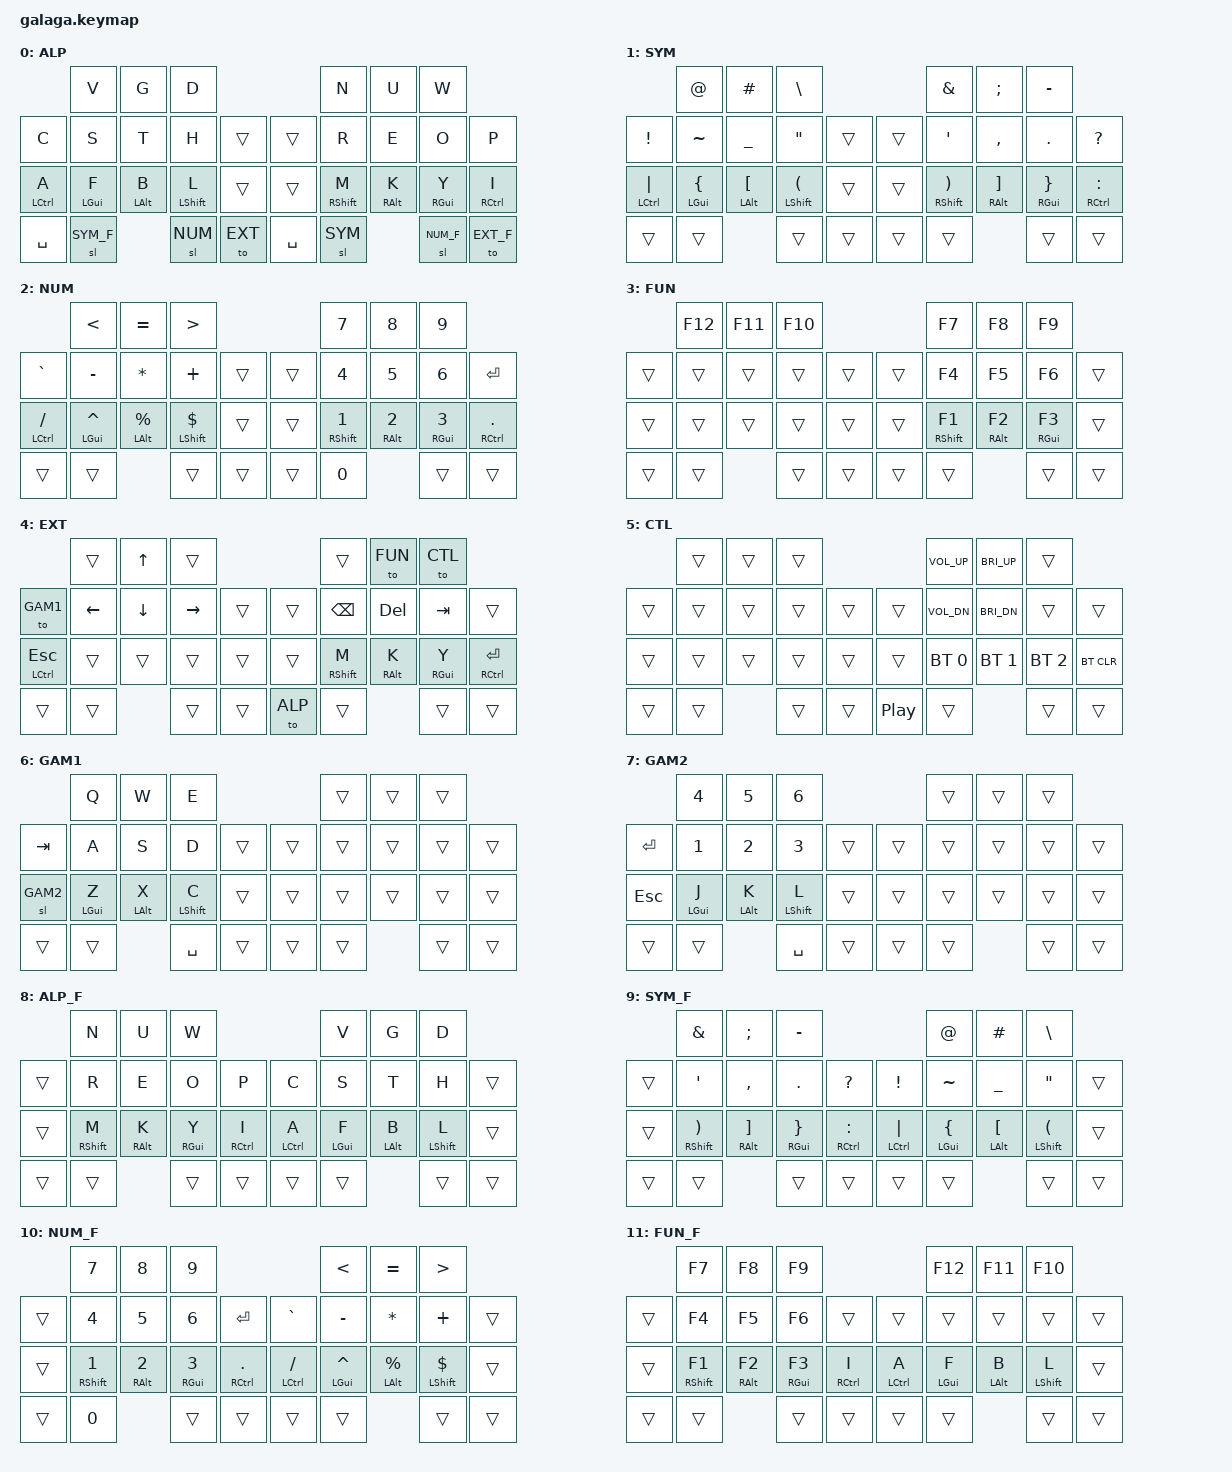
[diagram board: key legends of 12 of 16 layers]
#include <behaviors.dtsi>
#include <dt-bindings/zmk/keys.h>
#include <dt-bindings/zmk/bt.h>

/* Layers */
#define ALP 0
#define SYM 1
#define NUM 2
#define FUN 3
#define EXT 4
#define CTL 5
#define GAM1 6
#define GAM2 7
/* Flip hands */
#define ALP_F 8
#define SYM_F 9
#define NUM_F 10
#define FUN_F 11
#define EXT_F 12
#define CTL_F 13
#define GAM1_F 14
#define GAM2_F 15

/ {
  
  behaviors {
    hm: homerow_mods {
      compatible = "zmk,behavior-hold-tap";
      label = "HOMEROW_MODS";
      #binding-cells = <2>;
      tapping-term-ms = <300>;
      quick_tap_ms = <0>;
      flavor = "tap-preferred";
      bindings = <&kp>, <&kp>;
    };
  };

  /* TODO: figure out the correct key-positions for these combos */
  combos {
    compatible = "zmk,combos";
    combo_Z {
      layers = <0>;
      timeout-ms = <50>;
      key-positions = <17 18>;
      bindings = <&kp Z>;
    };
    combo_Q {
      layers = <0>;
      timeout-ms = <50>;
      key-positions = <18 19>;
      bindings = <&kp Q>;
    };
    combo_J {
      layers = <0>;
      timeout-ms = <50>;
      key-positions = <22 23>;
      bindings = <&kp J>;
    };
    combo_X {
      layers = <0>;
      timeout-ms = <50>;
      key-positions = <23 24>;
      bindings = <&kp X>;
    };
    combo_Z_F {
      layers = <8>;
      timeout-ms = <50>;
      key-positions = <22 23>;
      bindings = <&kp Z>;
    };
    combo_Q_F {
      layers = <8>;
      timeout-ms = <50>;
      key-positions = <23 24>;
      bindings = <&kp Q>;
    };
    combo_J_F {
      layers = <8>;
      timeout-ms = <50>;
      key-positions = <17 18>;
      bindings = <&kp J>;
    };
    combo_X_F {
      layers = <8>;
      timeout-ms = <50>;
      key-positions = <18 19>;
      bindings = <&kp X>;
    };
  };

  keymap {
    compatible = "zmk,keymap";

    ALP {
      bindings = <
                      &kp V       &kp G       &kp D                                      &kp N         &kp U       &kp W
        &kp C         &kp S       &kp T       &kp H         &trans            &trans     &kp R         &kp E       &kp O       &kp P
        &hm LCTRL A   &hm LGUI F  &hm LALT B  &hm LSHIFT L  &trans            &trans     &hm RSHIFT M  &hm RALT K  &hm RGUI Y  &hm RCTRL I
        &kp SPACE     &sl SYM_F               &sl NUM       &to EXT           &kp SPACE  &sl SYM                   &sl NUM_F   &to EXT_F
      >;
    };

    SYM {
      bindings = <
                        &kp AT         &kp HASH        &kp BSLH                                              &kp AMPS       &kp SEMI    &kp MINUS      
        &kp EXCL        &kp TILDE      &kp UNDER       &kp DQT            &trans            &trans           &kp SQT        &kp COMMA   &kp DOT    &kp QMARK
        &hm LCTRL PIPE  &hm LGUI LBRC  &hm LALT LBKT   &hm LSHIFT LPAR    &trans            &trans           &hm RSHIFT RPAR   &hm RALT RBKT  &hm RGUI RBRC &hm RCTRL COLON
        &trans          &trans                         &trans             &trans            &trans           &trans                     &trans     &trans
      >;
    };

    NUM {
      bindings = <
                        &kp LT         &kp EQUAL       &kp GT                                                &kp N7      &kp N8   &kp N9  
        &kp GRAVE       &kp MINUS      &kp STAR        &kp PLUS           &trans            &trans           &kp N4      &kp N5   &kp N6  &kp ENTER
        &hm LCTRL FSLH  &hm LGUI CARET &hm LALT PRCNT  &hm LSHIFT DLLR    &trans            &trans           &hm RSHIFT N1   &hm RALT N2  &hm RGUI N3 &hm RCTRL DOT
        &trans          &trans                         &trans             &trans            &trans           &kp N0                  &trans     &trans    
      >;
    };

    FUN {
      bindings = <
                        &kp F12        &kp F11         &kp F10                                               &kp F7         &kp F8      &kp F9      
        &trans          &trans         &trans          &trans             &trans            &trans           &kp F4         &kp F5      &kp F6     &trans    
        &trans          &trans         &trans          &trans             &trans            &trans           &hm RSHIFT F1  &hm RALT F2 &hm RGUI F3 &trans     
        &trans          &trans                         &trans             &trans            &trans           &trans                     &trans     &trans    
      >;
    };

    EXT {
      bindings = <
                        &trans         &kp UP          &trans                                                &trans         &to FUN     &to CTL    
        &to GAM1        &kp LEFT       &kp DOWN        &kp RIGHT          &trans            &trans           &kp BSPC       &kp DEL     &kp TAB    &trans    
        &hm LCTRL ESC   &trans         &trans          &trans             &trans            &trans           &hm RSHIFT M   &hm RALT K  &hm RGUI Y &hm RCTRL ENTER
        &trans          &trans                         &trans             &trans            &to ALP          &trans                     &trans     &trans    
      >;
    };

    CTL {
      bindings = <
                        &trans         &trans          &trans                                                &kp C_VOL_UP   &kp C_BRI_UP  &trans
        &trans          &trans         &trans          &trans             &trans            &trans           &kp C_VOL_DN   &kp C_BRI_DN  &trans        &trans
        &trans          &trans         &trans          &trans             &trans            &trans           &bt BT_SEL 0   &bt BT_SEL 1  &bt BT_SEL 2  &bt BT_CLR
        &trans          &trans                         &trans             &trans            &kp C_PP         &trans                       &trans        &trans
      >;
    };

    GAM1 {
      bindings = <
                        &kp Q          &kp W           &kp E                                                 &trans         &trans      &trans     
        &kp TAB         &kp A          &kp S           &kp D              &trans            &trans           &trans         &trans      &trans     &trans    
        &sl GAM2        &hm LGUI Z     &hm LALT X      &hm LSHIFT C       &trans            &trans           &trans         &trans      &trans     &trans     
        &trans          &trans                         &kp SPACE          &trans            &trans           &trans                     &trans     &trans    
      >;
    };

    GAM2 {
      bindings = <
                        &kp N4      &kp N5       &kp N6                                             &trans         &trans      &trans     
        &kp ENTER       &kp N1      &kp N2       &kp N3          &trans            &trans           &trans         &trans      &trans     &trans    
        &kp ESC         &hm LGUI J     &hm LALT K      &hm LSHIFT L       &trans            &trans           &trans         &trans      &trans     &trans     
        &trans          &trans                         &kp SPACE          &trans            &trans           &trans                     &trans     &trans    
      >;
    };

    ALP_F {
      bindings = <
                            &kp N          &kp U       &kp W                                             &kp V          &kp G           &kp D                     
           &trans           &kp R          &kp E       &kp O      &kp P                  &kp C           &kp S          &kp T           &kp H              &trans 
           &trans           &hm RSHIFT M   &hm RALT K  &hm RGUI Y &hm RCTRL I            &hm LCTRL A     &hm LGUI F     &hm LALT B      &hm LSHIFT L       &trans 
           &trans           &trans                     &trans     &trans                 &trans          &trans                         &trans             &trans   
      >;
    };

    SYM_F {
      bindings = <
                             &kp AMPS       &kp SEMI    &kp MINUS                                                  &kp AT         &kp HASH        &kp BSLH                 
            &trans           &kp SQT        &kp COMMA   &kp DOT    &kp QMARK                       &kp EXCL        &kp TILDE      &kp UNDER       &kp DQT            &trans
            &trans           &hm RSHIFT RPAR   &hm RALT RBKT  &hm RGUI RBRC &hm RCTRL COLON        &hm LCTRL PIPE  &hm LGUI LBRC  &hm LALT LBKT   &hm LSHIFT LPAR    &trans
            &trans           &trans                     &trans     &trans                          &trans          &trans                         &trans             &trans
      >;
    };

    NUM_F {
      bindings = <
                             &kp N7      &kp N8   &kp N9                                                    &kp LT         &kp EQUAL       &kp GT                   
            &trans           &kp N4      &kp N5   &kp N6  &kp ENTER                         &kp GRAVE       &kp MINUS      &kp STAR        &kp PLUS           &trans
            &trans           &hm RSHIFT N1   &hm RALT N2  &hm RGUI N3 &hm RCTRL DOT         &hm LCTRL FSLH  &hm LGUI CARET &hm LALT PRCNT  &hm LSHIFT DLLR    &trans
            &trans           &kp N0                  &trans     &trans                            &trans          &trans                         &trans             &trans
      >;
    };

    FUN_F {
      bindings = <
                             &kp F7         &kp F8      &kp F9                                     &kp F12        &kp F11         &kp F10                  
            &trans           &kp F4         &kp F5      &kp F6     &trans          &trans          &trans         &trans          &trans             &trans  
            &trans           &hm RSHIFT F1  &hm RALT F2 &hm RGUI F3 &hm RCTRL I    &hm LCTRL A     &hm LGUI F     &hm LALT B      &hm LSHIFT L       &trans 
            &trans           &trans                     &trans     &trans          &trans          &trans                         &trans             &trans  
      >;
    };

    EXT_F {
      bindings = <
                             &trans         &to FUN_F   &to CTL_F                                          &trans         &kp UP          &trans                   
            &trans           &kp BSPC       &kp DEL     &kp TAB    &trans                  &to GAM1_F      &kp LEFT       &kp DOWN        &kp RIGHT          &trans
            &trans           &hm RSHIFT M   &hm RALT K  &hm RGUI Y &hm RCTRL ENTER         &hm LCTRL ESC   &hm LGUI F     &hm LALT B      &hm LSHIFT L       &trans
            &to ALP_F        &trans                     &trans     &trans                  &trans          &trans                         &trans             &trans
      >;
    };

    CTL_F {
      bindings = <
                             &kp C_VOL_UP   &kp C_BRI_UP  &trans                                            &trans         &trans          &trans                   
            &trans           &kp C_VOL_DN   &kp C_BRI_DN  &trans        &trans              &trans          &trans         &trans          &trans             &trans
            &trans           &bt BT_SEL 0   &bt BT_SEL 1  &bt BT_SEL 2  &bt BT_CLR          &hm LCTRL A     &hm LGUI F     &hm LALT B      &hm LSHIFT L       &trans 
            &kp C_PP         &trans                       &trans        &trans              &trans          &trans                         &trans             &trans
      >;
    };

    GAM1_F {
      bindings = <
                             &trans         &trans      &trans                                    &kp Q          &kp W           &kp E                    
            &trans           &trans         &trans      &trans     &trans         &kp TAB      &kp A          &kp S           &kp D              &trans   
            &trans           &hm RSHIFT M   &hm RALT K  &hm RGUI Y &hm RCTRL I    &sl GAM2_F   &hm LGUI Z     &hm LALT X      &hm LSHIFT C       &trans    
            &trans           &trans                     &trans     &trans         &trans          &trans                         &kp SPACE          &trans   
      >;
    };

    GAM2_F {
      bindings = <
                             &trans         &trans      &trans                                    &kp N4      &kp N5       &kp N6                
            &trans           &trans         &trans      &trans     &trans         &kp ENTER       &kp N1      &kp N2       &kp N3          &trans   
            &trans           &trans         &trans      &trans     &trans         &kp ESC         &hm LGUI J     &hm LALT K      &hm LSHIFT L       &trans    
            &trans           &trans                     &trans     &trans         &trans          &trans                         &kp SPACE          &trans   
      >;
    };

  };
};
